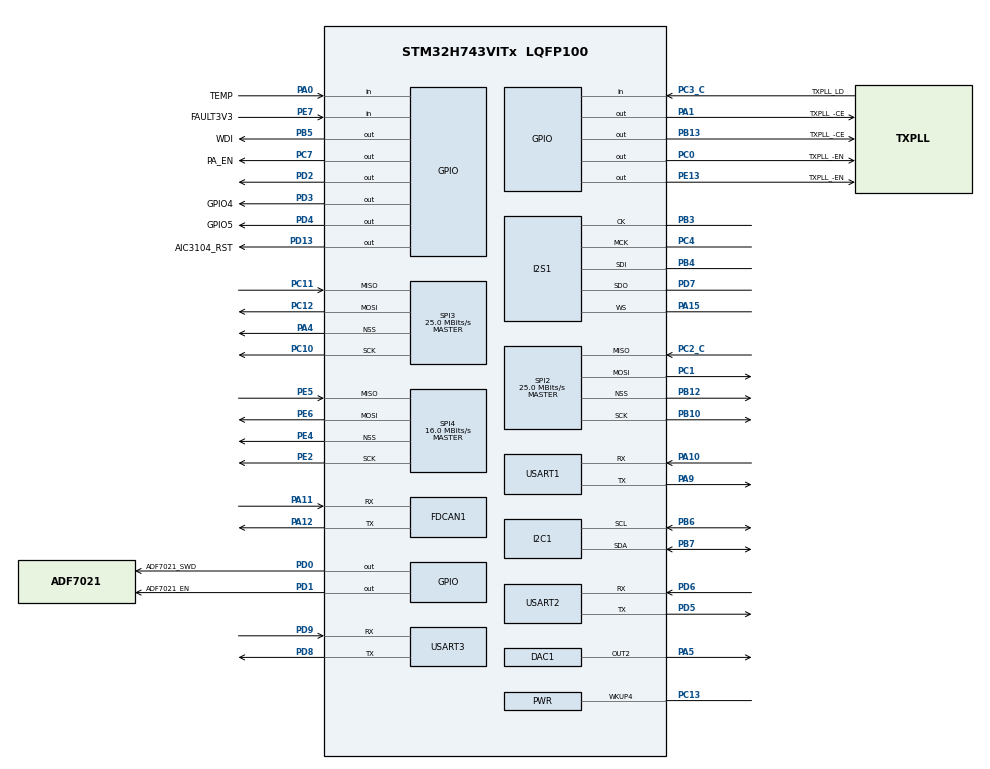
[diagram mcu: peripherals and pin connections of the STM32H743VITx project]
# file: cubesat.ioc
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CORTEX_M7.default_mode_Activation=1
DAC1.DAC_Channel-DAC_OUT2=DAC_CHANNEL_2
FDCAN1.CalculateBaudRateNominal=1041666
FDCAN1.CalculateTimeBitNominal=960
FDCAN1.CalculateTimeQuantumNominal=320.0
FDCAN1.TxBuffersNbr=32
FREERTOS.Tasks01=defaultTask,0,128,StartDefaultTask,Default,NULL,Dynamic,NULL,NULL
I2C1.Timing=0x00707CBB
I2S1.ErrorAudioFreq=1.72 %
I2S1.Instance=SPI$Index
I2S1.RealAudioFreq=8.138 KHz
Mcu.Family=STM32H7
Mcu.Name=STM32H743VITx
Mcu.Package=LQFP100
NVIC.PriorityGroup=NVIC_PRIORITYGROUP_4
NVIC.TIM1_UP_IRQn=true\:15\:0\:false\:false\:true\:false\:false\:true\:true
NVIC.TimeBase=TIM1_UP_IRQn
NVIC.TimeBaseIP=TIM1
PA0.GPIO_Label=TEMP
PA0.Signal=GPIO_Input
PA1.GPIO_Label=TXPLL_-CE
PA1.Signal=GPIO_Output
PA10.Mode=Asynchronous
PA10.Signal=USART1_RX
PA11.Mode=FDCAN_Activate
PA11.Signal=FDCAN1_RX
PA12.Mode=FDCAN_Activate
PA12.Signal=FDCAN1_TX
PA13\ (JTMS/SWDIO).Mode=Serial_Wire
PA13\ (JTMS/SWDIO).Signal=DEBUG_JTMS-SWDIO
PA14\ (JTCK/SWCLK).Mode=Serial_Wire
PA14\ (JTCK/SWCLK).Signal=DEBUG_JTCK-SWCLK
PA15\ (JTDI).Mode=Full_Duplex_Master
PA15\ (JTDI).Signal=I2S1_WS
PA4.Mode=NSS_Signal_Hard_Output
PA4.Signal=SPI3_NSS
PA5.Signal=COMP_DAC12_group
PA9.Mode=Asynchronous
PA9.Signal=USART1_TX
PB10.Mode=Full_Duplex_Master
PB10.Signal=SPI2_SCK
PB12.Mode=NSS_Signal_Hard_Output
PB12.Signal=SPI2_NSS
PB13.GPIO_Label=TXPLL_-CE
PB13.Signal=GPIO_Output
PB3\ (JTDO/TRACESWO).Mode=Full_Duplex_Master
PB3\ (JTDO/TRACESWO).Signal=I2S1_CK
PB4\ (NJTRST).Mode=Full_Duplex_Master
PB4\ (NJTRST).Signal=I2S1_SDI
PB5.GPIO_Label=WDI
PB5.Signal=GPIO_Output
PB6.Mode=I2C
PB6.Signal=I2C1_SCL
PB7.Mode=I2C
PB7.Signal=I2C1_SDA
PC0.GPIO_Label=TXPLL_-EN
PC0.Signal=GPIO_Output
PC1.Mode=Full_Duplex_Master
PC1.Signal=SPI2_MOSI
PC10.Mode=Full_Duplex_Master
PC10.Signal=SPI3_SCK
PC11.Mode=Full_Duplex_Master
PC11.Signal=SPI3_MISO
PC12.Mode=Full_Duplex_Master
PC12.Signal=SPI3_MOSI
PC13.Mode=WakeUp4
PC13.Signal=PWR_WKUP4
PC14-OSC32_IN\ (OSC32_IN).Mode=LSE-External-Clock-Source
PC14-OSC32_IN\ (OSC32_IN).Signal=RCC_OSC32_IN
PC2_C.Mode=Full_Duplex_Master
PC2_C.Signal=SPI2_MISO
PC3_C.GPIO_Label=TXPLL_LD
PC3_C.Signal=GPIO_Input
PC4.Mode=Master_Clock_Activated
PC4.Signal=I2S1_MCK
PC7.GPIO_Label=PA_EN
PC7.Signal=GPIO_Output
PD0.GPIO_Label=ADF7021_SWD
PD0.Signal=GPIO_Output
PD1.GPIO_Label=ADF7021_EN
PD1.Signal=GPIO_Output
PD13.GPIO_Label=AIC3104_RST
PD13.Signal=GPIO_Output
PD2.Signal=GPIO_Output
PD3.GPIO_Label=GPIO4
PD3.Signal=GPIO_Output
PD4.GPIO_Label=GPIO5
PD4.Signal=GPIO_Output
PD5.Mode=Asynchronous
PD5.Signal=USART2_TX
PD6.Mode=Asynchronous
PD6.Signal=USART2_RX
PD7.Mode=Full_Duplex_Master
PD7.Signal=I2S1_SDO
PD8.Mode=Asynchronous
PD8.Signal=USART3_TX
PD9.Mode=Asynchronous
PD9.Signal=USART3_RX
PE13.GPIO_Label=TXPLL_-EN
PE13.Signal=GPIO_Output
PE2.Mode=Full_Duplex_Master
PE2.Signal=SPI4_SCK
PE4.Mode=NSS_Signal_Hard_Output
PE4.Signal=SPI4_NSS
PE5.Mode=Full_Duplex_Master
PE5.Signal=SPI4_MISO
PE6.Mode=Full_Duplex_Master
PE6.Signal=SPI4_MOSI
PE7.GPIO_Label=FAULT3V3
PE7.Signal=GPIO_Input
PH0-OSC_IN\ (PH0).Mode=HSE-External-Clock-Source
PH0-OSC_IN\ (PH0).Signal=RCC_OSC_IN
ProjectManager.HeapSize=0x200
ProjectManager.StackSize=0x400
ProjectManager.TargetToolchain=CMake
RCC.ADCFreq_Value=129000000
RCC.APB1Freq_Value=32000000
RCC.APB2Freq_Value=32000000
RCC.APB3Freq_Value=64000000
RCC.APB4Freq_Value=32000000
RCC.CortexFreq_Value=64000000
RCC.D2PPRE1=RCC_APB1_DIV2
RCC.D2PPRE2=RCC_APB2_DIV2
RCC.D3PPRE=RCC_APB4_DIV2
RCC.DIVM1=4
RCC.DIVN1=9
RCC.DIVQ1=3
RCC.HCLKFreq_Value=64000000
RCC.PLL2FRACN=0
RCC.PLL3FRACN=0
RCC.PLLFRACN=3072
RCC.SYSCLKFreq_VALUE=64000000
RCC.USBFreq_Value=50000000
SH.COMP_DAC12_group.0=DAC1_OUT2,DAC_OUT2
SPI2.CalculateBaudRate=25.0 MBits/s
SPI2.Direction=SPI_DIRECTION_2LINES
SPI2.Mode=SPI_MODE_MASTER
SPI2.VirtualNSS=VM_NSSHARD
SPI2.VirtualType=VM_MASTER
SPI3.CalculateBaudRate=25.0 MBits/s
SPI3.Direction=SPI_DIRECTION_2LINES
SPI3.Mode=SPI_MODE_MASTER
SPI3.VirtualNSS=VM_NSSHARD
SPI3.VirtualType=VM_MASTER
SPI4.CalculateBaudRate=16.0 MBits/s
SPI4.Direction=SPI_DIRECTION_2LINES
SPI4.Mode=SPI_MODE_MASTER
SPI4.VirtualNSS=VM_NSSHARD
SPI4.VirtualType=VM_MASTER
STMicroelectronics.X-CUBE-ALGOBUILD.1.4.0.LibraryCcDSPOoLibraryJjDSPOoLibrary=true
USART1.VirtualMode-Asynchronous=VM_ASYNC
USART2.VirtualMode-Asynchronous=VM_ASYNC
USART3.VirtualMode-Asynchronous=VM_ASYNC
VP_FREERTOS_VS_CMSIS_V1.Mode=CMSIS_V1
VP_IWDG1_VS_IWDG.Mode=IWDG_Activate
VP_MEMORYMAP_VS_MEMORYMAP.Mode=CurAppReg
VP_STMicroelectronics.X-CUBE-ALGOBUILD_VS_DSPOoLibraryJjLibrary_1.4.0_1.4.0.Mode=DSPOoLibraryJjLibrary
VP_SYS_VS_tim1.Mode=TIM1
board=custom

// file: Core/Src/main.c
/* USER CODE BEGIN Header */
/**
  ******************************************************************************
  * @file           : main.c
  * @brief          : Main program body
  ******************************************************************************
  * @attention
  *
  * Copyright (c) 2026 STMicroelectronics.
  * All rights reserved.
  *
  * This software is licensed under terms that can be found in the LICENSE file
  * in the root directory of this software component.
  * If no LICENSE file comes with this software, it is provided AS-IS.
  *
  ******************************************************************************
  */
/* USER CODE END Header */
#include "main.h"
#include "cmsis_os.h"
#include "stm32h7xx_hal_dac.h"

/* USER CODE BEGIN Includes */
#include "aic3104.h"
/* USER CODE END Includes */

DAC_HandleTypeDef hdac1;

FDCAN_HandleTypeDef hfdcan1;

I2C_HandleTypeDef hi2c1;

I2S_HandleTypeDef hi2s1;

IWDG_HandleTypeDef hiwdg1;

SPI_HandleTypeDef hspi2;
SPI_HandleTypeDef hspi3;
SPI_HandleTypeDef hspi4;

UART_HandleTypeDef huart1;
UART_HandleTypeDef huart2;
UART_HandleTypeDef huart3;

osThreadId defaultTaskHandle;

void SystemClock_Config(void);
static void MPU_Config(void);
static void MX_GPIO_Init(void);
static void MX_FDCAN1_Init(void);
static void MX_I2S1_Init(void);
static void MX_SPI4_Init(void);
static void MX_SPI2_Init(void);
static void MX_SPI3_Init(void);
static void MX_DAC1_Init(void);
static void MX_I2C1_Init(void);
static void MX_IWDG1_Init(void);
static void MX_USART1_UART_Init(void);
static void MX_USART2_UART_Init(void);
static void MX_USART3_UART_Init(void);
void StartDefaultTask(void const * argument);

int main(void)
{

  /* MPU Configuration--------------------------------------------------------*/
  MPU_Config();

  /* MCU Configuration--------------------------------------------------------*/

  /* Reset of all peripherals, Initializes the Flash interface and the Systick. */
  HAL_Init();

  /* Configure the system clock */
  SystemClock_Config();

  /* Initialize all configured peripherals */
  MX_GPIO_Init();
  MX_FDCAN1_Init();
  MX_I2S1_Init();
  MX_SPI4_Init();
  MX_SPI2_Init();
  MX_SPI3_Init();
  MX_DAC1_Init();
  MX_I2C1_Init();
  MX_IWDG1_Init();
  MX_USART1_UART_Init();
  MX_USART2_UART_Init();
  MX_USART3_UART_Init();
  /* USER CODE BEGIN 2 */

  /* Initialize AIC3104 codec */
  AIC3104_Config_t aic3104_cfg = {
      .hi2c = &hi2c1,
      .hi2s = &hi2s1,
      .reset_port = GPIOD,
      .reset_pin = AIC3104_RST_Pin,
      .mclk_freq = 12288000,     /* 12.288 MHz MCLK */
      .sample_rate = AIC3104_FS_48K,
      .i2s_mode = AIC3104_MODE_MASTER
  };

  if (AIC3104_Init(&aic3104_cfg) != HAL_OK) {
      Error_Handler();
  }

  /* USER CODE END 2 */

  /* Create the thread(s) */
  /* definition and creation of defaultTask */
  osThreadDef(defaultTask, StartDefaultTask, osPriorityNormal, 0, 128);
  defaultTaskHandle = osThreadCreate(osThread(defaultTask), NULL);

  /* Start scheduler */
  osKernelStart();

  /* We should never get here as control is now taken by the scheduler */

  /* Infinite loop */
  while (1)
  {

  }
}

void SystemClock_Config(void)
{
  RCC_OscInitTypeDef RCC_OscInitStruct = {0};
  RCC_ClkInitTypeDef RCC_ClkInitStruct = {0};

  /** Supply configuration update enable
  */
  HAL_PWREx_ConfigSupply(PWR_LDO_SUPPLY);

  /** Configure the main internal regulator output voltage
  */
  __HAL_PWR_VOLTAGESCALING_CONFIG(PWR_REGULATOR_VOLTAGE_SCALE3);

  while(!__HAL_PWR_GET_FLAG(PWR_FLAG_VOSRDY)) {}

  /** Initializes the RCC Oscillators according to the specified parameters
  * in the RCC_OscInitTypeDef structure.
  */
  RCC_OscInitStruct.OscillatorType = RCC_OSCILLATORTYPE_HSI|RCC_OSCILLATORTYPE_LSI;
  RCC_OscInitStruct.HSIState = RCC_HSI_DIV1;
  RCC_OscInitStruct.HSICalibrationValue = RCC_HSICALIBRATION_DEFAULT;
  RCC_OscInitStruct.LSIState = RCC_LSI_ON;
  RCC_OscInitStruct.PLL.PLLState = RCC_PLL_ON;
  RCC_OscInitStruct.PLL.PLLSource = RCC_PLLSOURCE_HSI;
  RCC_OscInitStruct.PLL.PLLM = 4;
  RCC_OscInitStruct.PLL.PLLN = 9;
  RCC_OscInitStruct.PLL.PLLP = 2;
  RCC_OscInitStruct.PLL.PLLQ = 3;
  RCC_OscInitStruct.PLL.PLLR = 2;
  RCC_OscInitStruct.PLL.PLLRGE = RCC_PLL1VCIRANGE_3;
  RCC_OscInitStruct.PLL.PLLVCOSEL = RCC_PLL1VCOMEDIUM;
  RCC_OscInitStruct.PLL.PLLFRACN = 3072;
  if (HAL_RCC_OscConfig(&RCC_OscInitStruct) != HAL_OK)
  {
    Error_Handler();
  }

  /** Initializes the CPU, AHB and APB buses clocks
  */
  RCC_ClkInitStruct.ClockType = RCC_CLOCKTYPE_HCLK|RCC_CLOCKTYPE_SYSCLK
                              |RCC_CLOCKTYPE_PCLK1|RCC_CLOCKTYPE_PCLK2
                              |RCC_CLOCKTYPE_D3PCLK1|RCC_CLOCKTYPE_D1PCLK1;
  RCC_ClkInitStruct.SYSCLKSource = RCC_SYSCLKSOURCE_HSI;
  RCC_ClkInitStruct.SYSCLKDivider = RCC_SYSCLK_DIV1;
  RCC_ClkInitStruct.AHBCLKDivider = RCC_HCLK_DIV1;
  RCC_ClkInitStruct.APB3CLKDivider = RCC_APB3_DIV1;
  RCC_ClkInitStruct.APB1CLKDivider = RCC_APB1_DIV2;
  RCC_ClkInitStruct.APB2CLKDivider = RCC_APB2_DIV2;
  RCC_ClkInitStruct.APB4CLKDivider = RCC_APB4_DIV2;

  if (HAL_RCC_ClockConfig(&RCC_ClkInitStruct, FLASH_LATENCY_1) != HAL_OK)
  {
    Error_Handler();
  }
}

static void MX_DAC1_Init(void)
{

  DAC_ChannelConfTypeDef sConfig = {0};

  /** DAC Initialization
  */
  hdac1.Instance = DAC1;
  if (HAL_DAC_Init(&hdac1) != HAL_OK)
  {
    Error_Handler();
  }

  /** DAC channel OUT2 config
  */
  sConfig.DAC_SampleAndHold = DAC_SAMPLEANDHOLD_DISABLE;
  sConfig.DAC_Trigger = DAC_TRIGGER_NONE;
  sConfig.DAC_OutputBuffer = DAC_OUTPUTBUFFER_ENABLE;
  sConfig.DAC_ConnectOnChipPeripheral = DAC_CHIPCONNECT_DISABLE;
  sConfig.DAC_UserTrimming = DAC_TRIMMING_FACTORY;
  if (HAL_DAC_ConfigChannel(&hdac1, &sConfig, DAC_CHANNEL_2) != HAL_OK)
  {
    Error_Handler();
  }
  /* USER CODE BEGIN DAC1_Init 2 */
  HAL_DAC_SetValue(&hdac1, DAC_CHANNEL_2, DAC_ALIGN_12B_R, 2048);
  /* USER CODE END DAC1_Init 2 */

}

static void MX_FDCAN1_Init(void)
{

  hfdcan1.Instance = FDCAN1;
  hfdcan1.Init.FrameFormat = FDCAN_FRAME_CLASSIC;
  hfdcan1.Init.Mode = FDCAN_MODE_NORMAL;
  hfdcan1.Init.AutoRetransmission = DISABLE;
  hfdcan1.Init.TransmitPause = DISABLE;
  hfdcan1.Init.ProtocolException = DISABLE;
  hfdcan1.Init.NominalPrescaler = 16;
  hfdcan1.Init.NominalSyncJumpWidth = 1;
  hfdcan1.Init.NominalTimeSeg1 = 1;
  hfdcan1.Init.NominalTimeSeg2 = 1;
  hfdcan1.Init.DataPrescaler = 1;
  hfdcan1.Init.DataSyncJumpWidth = 1;
  hfdcan1.Init.DataTimeSeg1 = 1;
  hfdcan1.Init.DataTimeSeg2 = 1;
  hfdcan1.Init.MessageRAMOffset = 0;
  hfdcan1.Init.StdFiltersNbr = 0;
  hfdcan1.Init.ExtFiltersNbr = 0;
  hfdcan1.Init.RxFifo0ElmtsNbr = 0;
  hfdcan1.Init.RxFifo0ElmtSize = FDCAN_DATA_BYTES_8;
  hfdcan1.Init.RxFifo1ElmtsNbr = 0;
  hfdcan1.Init.RxFifo1ElmtSize = FDCAN_DATA_BYTES_8;
  hfdcan1.Init.RxBuffersNbr = 0;
  hfdcan1.Init.RxBufferSize = FDCAN_DATA_BYTES_8;
  hfdcan1.Init.TxEventsNbr = 0;
  hfdcan1.Init.TxBuffersNbr = 32;
  hfdcan1.Init.TxFifoQueueElmtsNbr = 0;
  hfdcan1.Init.TxFifoQueueMode = FDCAN_TX_FIFO_OPERATION;
  hfdcan1.Init.TxElmtSize = FDCAN_DATA_BYTES_8;
  if (HAL_FDCAN_Init(&hfdcan1) != HAL_OK)
  {
    Error_Handler();
  }

}

static void MX_I2C1_Init(void)
{

  hi2c1.Instance = I2C1;
  hi2c1.Init.Timing = 0x00707CBB;
  hi2c1.Init.OwnAddress1 = 0;
  hi2c1.Init.AddressingMode = I2C_ADDRESSINGMODE_7BIT;
  hi2c1.Init.DualAddressMode = I2C_DUALADDRESS_DISABLE;
  hi2c1.Init.OwnAddress2 = 0;
  hi2c1.Init.OwnAddress2Masks = I2C_OA2_NOMASK;
  hi2c1.Init.GeneralCallMode = I2C_GENERALCALL_DISABLE;
  hi2c1.Init.NoStretchMode = I2C_NOSTRETCH_DISABLE;
  if (HAL_I2C_Init(&hi2c1) != HAL_OK)
  {
    Error_Handler();
  }

  /** Configure Analogue filter
  */
  if (HAL_I2CEx_ConfigAnalogFilter(&hi2c1, I2C_ANALOGFILTER_ENABLE) != HAL_OK)
  {
    Error_Handler();
  }

  /** Configure Digital filter
  */
  if (HAL_I2CEx_ConfigDigitalFilter(&hi2c1, 0) != HAL_OK)
  {
    Error_Handler();
  }

}

static void MX_I2S1_Init(void)
{

  hi2s1.Instance = SPI1;
  hi2s1.Init.Mode = I2S_MODE_MASTER_FULLDUPLEX;
  hi2s1.Init.Standard = I2S_STANDARD_PHILIPS;
  hi2s1.Init.DataFormat = I2S_DATAFORMAT_16B;
  hi2s1.Init.MCLKOutput = I2S_MCLKOUTPUT_ENABLE;
  hi2s1.Init.AudioFreq = I2S_AUDIOFREQ_8K;
  hi2s1.Init.CPOL = I2S_CPOL_LOW;
  hi2s1.Init.FirstBit = I2S_FIRSTBIT_MSB;
  hi2s1.Init.WSInversion = I2S_WS_INVERSION_DISABLE;
  hi2s1.Init.Data24BitAlignment = I2S_DATA_24BIT_ALIGNMENT_RIGHT;
  hi2s1.Init.MasterKeepIOState = I2S_MASTER_KEEP_IO_STATE_DISABLE;
  if (HAL_I2S_Init(&hi2s1) != HAL_OK)
  {
    Error_Handler();
  }

}

static void MX_IWDG1_Init(void)
{

  hiwdg1.Instance = IWDG1;
  hiwdg1.Init.Prescaler = IWDG_PRESCALER_4;
  hiwdg1.Init.Window = 4095;
  hiwdg1.Init.Reload = 4095;
  if (HAL_IWDG_Init(&hiwdg1) != HAL_OK)
  {
    Error_Handler();
  }

}

static void MX_SPI2_Init(void)
{

  /* SPI2 parameter configuration*/
  hspi2.Instance = SPI2;
  hspi2.Init.Mode = SPI_MODE_MASTER;
  hspi2.Init.Direction = SPI_DIRECTION_2LINES;
  hspi2.Init.DataSize = SPI_DATASIZE_4BIT;
  hspi2.Init.CLKPolarity = SPI_POLARITY_LOW;
  hspi2.Init.CLKPhase = SPI_PHASE_1EDGE;
  hspi2.Init.NSS = SPI_NSS_HARD_OUTPUT;
  hspi2.Init.BaudRatePrescaler = SPI_BAUDRATEPRESCALER_2;
  hspi2.Init.FirstBit = SPI_FIRSTBIT_MSB;
  hspi2.Init.TIMode = SPI_TIMODE_DISABLE;
  hspi2.Init.CRCCalculation = SPI_CRCCALCULATION_DISABLE;
  hspi2.Init.CRCPolynomial = 0x0;
  hspi2.Init.NSSPMode = SPI_NSS_PULSE_ENABLE;
  hspi2.Init.NSSPolarity = SPI_NSS_POLARITY_LOW;
  hspi2.Init.FifoThreshold = SPI_FIFO_THRESHOLD_01DATA;
  hspi2.Init.TxCRCInitializationPattern = SPI_CRC_INITIALIZATION_ALL_ZERO_PATTERN;
  hspi2.Init.RxCRCInitializationPattern = SPI_CRC_INITIALIZATION_ALL_ZERO_PATTERN;
  hspi2.Init.MasterSSIdleness = SPI_MASTER_SS_IDLENESS_00CYCLE;
  hspi2.Init.MasterInterDataIdleness = SPI_MASTER_INTERDATA_IDLENESS_00CYCLE;
  hspi2.Init.MasterReceiverAutoSusp = SPI_MASTER_RX_AUTOSUSP_DISABLE;
  hspi2.Init.MasterKeepIOState = SPI_MASTER_KEEP_IO_STATE_DISABLE;
  hspi2.Init.IOSwap = SPI_IO_SWAP_DISABLE;
  if (HAL_SPI_Init(&hspi2) != HAL_OK)
  {
    Error_Handler();
  }

}

static void MX_SPI3_Init(void)
{

  /* SPI3 parameter configuration*/
  hspi3.Instance = SPI3;
  hspi3.Init.Mode = SPI_MODE_MASTER;
  hspi3.Init.Direction = SPI_DIRECTION_2LINES;
  hspi3.Init.DataSize = SPI_DATASIZE_4BIT;
  hspi3.Init.CLKPolarity = SPI_POLARITY_LOW;
  hspi3.Init.CLKPhase = SPI_PHASE_1EDGE;
  hspi3.Init.NSS = SPI_NSS_HARD_OUTPUT;
  hspi3.Init.BaudRatePrescaler = SPI_BAUDRATEPRESCALER_2;
  hspi3.Init.FirstBit = SPI_FIRSTBIT_MSB;
  hspi3.Init.TIMode = SPI_TIMODE_DISABLE;
  hspi3.Init.CRCCalculation = SPI_CRCCALCULATION_DISABLE;
  hspi3.Init.CRCPolynomial = 0x0;
  hspi3.Init.NSSPMode = SPI_NSS_PULSE_ENABLE;
  hspi3.Init.NSSPolarity = SPI_NSS_POLARITY_LOW;
  hspi3.Init.FifoThreshold = SPI_FIFO_THRESHOLD_01DATA;
  hspi3.Init.TxCRCInitializationPattern = SPI_CRC_INITIALIZATION_ALL_ZERO_PATTERN;
  hspi3.Init.RxCRCInitializationPattern = SPI_CRC_INITIALIZATION_ALL_ZERO_PATTERN;
  hspi3.Init.MasterSSIdleness = SPI_MASTER_SS_IDLENESS_00CYCLE;
  hspi3.Init.MasterInterDataIdleness = SPI_MASTER_INTERDATA_IDLENESS_00CYCLE;
  hspi3.Init.MasterReceiverAutoSusp = SPI_MASTER_RX_AUTOSUSP_DISABLE;
  hspi3.Init.MasterKeepIOState = SPI_MASTER_KEEP_IO_STATE_DISABLE;
  hspi3.Init.IOSwap = SPI_IO_SWAP_DISABLE;
  if (HAL_SPI_Init(&hspi3) != HAL_OK)
  {
    Error_Handler();
  }

}

static void MX_SPI4_Init(void)
{

  /* SPI4 parameter configuration*/
  hspi4.Instance = SPI4;
  hspi4.Init.Mode = SPI_MODE_MASTER;
  hspi4.Init.Direction = SPI_DIRECTION_2LINES;
  hspi4.Init.DataSize = SPI_DATASIZE_4BIT;
  hspi4.Init.CLKPolarity = SPI_POLARITY_LOW;
  hspi4.Init.CLKPhase = SPI_PHASE_1EDGE;
  hspi4.Init.NSS = SPI_NSS_HARD_OUTPUT;
  hspi4.Init.BaudRatePrescaler = SPI_BAUDRATEPRESCALER_2;
  hspi4.Init.FirstBit = SPI_FIRSTBIT_MSB;
  hspi4.Init.TIMode = SPI_TIMODE_DISABLE;
  hspi4.Init.CRCCalculation = SPI_CRCCALCULATION_DISABLE;
  hspi4.Init.CRCPolynomial = 0x0;
  hspi4.Init.NSSPMode = SPI_NSS_PULSE_ENABLE;
  hspi4.Init.NSSPolarity = SPI_NSS_POLARITY_LOW;
  hspi4.Init.FifoThreshold = SPI_FIFO_THRESHOLD_01DATA;
  hspi4.Init.TxCRCInitializationPattern = SPI_CRC_INITIALIZATION_ALL_ZERO_PATTERN;
  hspi4.Init.RxCRCInitializationPattern = SPI_CRC_INITIALIZATION_ALL_ZERO_PATTERN;
  hspi4.Init.MasterSSIdleness = SPI_MASTER_SS_IDLENESS_00CYCLE;
  hspi4.Init.MasterInterDataIdleness = SPI_MASTER_INTERDATA_IDLENESS_00CYCLE;
  hspi4.Init.MasterReceiverAutoSusp = SPI_MASTER_RX_AUTOSUSP_DISABLE;
  hspi4.Init.MasterKeepIOState = SPI_MASTER_KEEP_IO_STATE_DISABLE;
  hspi4.Init.IOSwap = SPI_IO_SWAP_DISABLE;
  if (HAL_SPI_Init(&hspi4) != HAL_OK)
  {
    Error_Handler();
  }

}

static void MX_USART1_UART_Init(void)
{

  huart1.Instance = USART1;
  huart1.Init.BaudRate = 115200;
  huart1.Init.WordLength = UART_WORDLENGTH_8B;
  huart1.Init.StopBits = UART_STOPBITS_1;
  huart1.Init.Parity = UART_PARITY_NONE;
  huart1.Init.Mode = UART_MODE_TX_RX;
  huart1.Init.HwFlowCtl = UART_HWCONTROL_NONE;
  huart1.Init.OverSampling = UART_OVERSAMPLING_16;
  huart1.Init.OneBitSampling = UART_ONE_BIT_SAMPLE_DISABLE;
  huart1.Init.ClockPrescaler = UART_PRESCALER_DIV1;
  huart1.AdvancedInit.AdvFeatureInit = UART_ADVFEATURE_NO_INIT;
  if (HAL_UART_Init(&huart1) != HAL_OK)
  {
    Error_Handler();
  }
  if (HAL_UARTEx_SetTxFifoThreshold(&huart1, UART_TXFIFO_THRESHOLD_1_8) != HAL_OK)
  {
    Error_Handler();
  }
  if (HAL_UARTEx_SetRxFifoThreshold(&huart1, UART_RXFIFO_THRESHOLD_1_8) != HAL_OK)
  {
    Error_Handler();
  }
  if (HAL_UARTEx_DisableFifoMode(&huart1) != HAL_OK)
  {
    Error_Handler();
  }

}

static void MX_USART2_UART_Init(void)
{

  huart2.Instance = USART2;
  huart2.Init.BaudRate = 115200;
  huart2.Init.WordLength = UART_WORDLENGTH_8B;
  huart2.Init.StopBits = UART_STOPBITS_1;
  huart2.Init.Parity = UART_PARITY_NONE;
  huart2.Init.Mode = UART_MODE_TX_RX;
  huart2.Init.HwFlowCtl = UART_HWCONTROL_NONE;
  huart2.Init.OverSampling = UART_OVERSAMPLING_16;
  huart2.Init.OneBitSampling = UART_ONE_BIT_SAMPLE_DISABLE;
  huart2.Init.ClockPrescaler = UART_PRESCALER_DIV1;
  huart2.AdvancedInit.AdvFeatureInit = UART_ADVFEATURE_NO_INIT;
  if (HAL_UART_Init(&huart2) != HAL_OK)
  {
    Error_Handler();
  }
  if (HAL_UARTEx_SetTxFifoThreshold(&huart2, UART_TXFIFO_THRESHOLD_1_8) != HAL_OK)
  {
    Error_Handler();
  }
  if (HAL_UARTEx_SetRxFifoThreshold(&huart2, UART_RXFIFO_THRESHOLD_1_8) != HAL_OK)
  {
    Error_Handler();
  }
  if (HAL_UARTEx_DisableFifoMode(&huart2) != HAL_OK)
  {
    Error_Handler();
  }

}

static void MX_USART3_UART_Init(void)
{

  huart3.Instance = USART3;
  huart3.Init.BaudRate = 115200;
  huart3.Init.WordLength = UART_WORDLENGTH_8B;
  huart3.Init.StopBits = UART_STOPBITS_1;
  huart3.Init.Parity = UART_PARITY_NONE;
  huart3.Init.Mode = UART_MODE_TX_RX;
  huart3.Init.HwFlowCtl = UART_HWCONTROL_NONE;
  huart3.Init.OverSampling = UART_OVERSAMPLING_16;
  huart3.Init.OneBitSampling = UART_ONE_BIT_SAMPLE_DISABLE;
  huart3.Init.ClockPrescaler = UART_PRESCALER_DIV1;
  huart3.AdvancedInit.AdvFeatureInit = UART_ADVFEATURE_NO_INIT;
  if (HAL_UART_Init(&huart3) != HAL_OK)
  {
    Error_Handler();
  }
  if (HAL_UARTEx_SetTxFifoThreshold(&huart3, UART_TXFIFO_THRESHOLD_1_8) != HAL_OK)
  {
    Error_Handler();
  }
  if (HAL_UARTEx_SetRxFifoThreshold(&huart3, UART_RXFIFO_THRESHOLD_1_8) != HAL_OK)
  {
    Error_Handler();
  }
  if (HAL_UARTEx_DisableFifoMode(&huart3) != HAL_OK)
  {
    Error_Handler();
  }

}

static void MX_GPIO_Init(void)
{
  GPIO_InitTypeDef GPIO_InitStruct = {0};

  /* GPIO Ports Clock Enable */
  __HAL_RCC_GPIOE_CLK_ENABLE();
  __HAL_RCC_GPIOC_CLK_ENABLE();
  __HAL_RCC_GPIOH_CLK_ENABLE();
  __HAL_RCC_GPIOA_CLK_ENABLE();
  __HAL_RCC_GPIOB_CLK_ENABLE();
  __HAL_RCC_GPIOD_CLK_ENABLE();

  /*Configure GPIO pin Output Level */
  HAL_GPIO_WritePin(GPIOC, TXPLL__EN_Pin|PA_EN_Pin, GPIO_PIN_RESET);

  /*Configure GPIO pin Output Level */
  HAL_GPIO_WritePin(TXPLL__CE_GPIO_Port, TXPLL__CE_Pin, GPIO_PIN_RESET);

  /*Configure GPIO pin Output Level */
  HAL_GPIO_WritePin(TXPLL__ENE13_GPIO_Port, TXPLL__ENE13_Pin, GPIO_PIN_RESET);

  /*Configure GPIO pin Output Level */
  HAL_GPIO_WritePin(GPIOB, TXPLL__CEB13_Pin|WDI_Pin, GPIO_PIN_RESET);

  /*Configure GPIO pin Output Level */
  HAL_GPIO_WritePin(GPIOD, AIC3104_RST_Pin|ADF7021_SWD_Pin|ADF7021_EN_Pin|GPIO_PIN_2
                          |GPIO4_Pin|GPIO5_Pin, GPIO_PIN_RESET);

  /*Configure GPIO pins : TXPLL__EN_Pin PA_EN_Pin */
  GPIO_InitStruct.Pin = TXPLL__EN_Pin|PA_EN_Pin;
  GPIO_InitStruct.Mode = GPIO_MODE_OUTPUT_PP;
  GPIO_InitStruct.Pull = GPIO_NOPULL;
  GPIO_InitStruct.Speed = GPIO_SPEED_FREQ_LOW;
  HAL_GPIO_Init(GPIOC, &GPIO_InitStruct);

  /*Configure GPIO pin : TXPLL_LD_Pin */
  GPIO_InitStruct.Pin = TXPLL_LD_Pin;
  GPIO_InitStruct.Mode = GPIO_MODE_INPUT;
  GPIO_InitStruct.Pull = GPIO_NOPULL;
  HAL_GPIO_Init(TXPLL_LD_GPIO_Port, &GPIO_InitStruct);

  /*Configure GPIO pin : TEMP_Pin */
  GPIO_InitStruct.Pin = TEMP_Pin;
  GPIO_InitStruct.Mode = GPIO_MODE_INPUT;
  GPIO_InitStruct.Pull = GPIO_NOPULL;
  HAL_GPIO_Init(TEMP_GPIO_Port, &GPIO_InitStruct);

  /*Configure GPIO pin : TXPLL__CE_Pin */
  GPIO_InitStruct.Pin = TXPLL__CE_Pin;
  GPIO_InitStruct.Mode = GPIO_MODE_OUTPUT_PP;
  GPIO_InitStruct.Pull = GPIO_NOPULL;
  GPIO_InitStruct.Speed = GPIO_SPEED_FREQ_LOW;
  HAL_GPIO_Init(TXPLL__CE_GPIO_Port, &GPIO_InitStruct);

  /*Configure GPIO pin : FAULT3V3_Pin */
  GPIO_InitStruct.Pin = FAULT3V3_Pin;
  GPIO_InitStruct.Mode = GPIO_MODE_INPUT;
  GPIO_InitStruct.Pull = GPIO_NOPULL;
  HAL_GPIO_Init(FAULT3V3_GPIO_Port, &GPIO_InitStruct);

  /*Configure GPIO pin : TXPLL__ENE13_Pin */
  GPIO_InitStruct.Pin = TXPLL__ENE13_Pin;
  GPIO_InitStruct.Mode = GPIO_MODE_OUTPUT_PP;
  GPIO_InitStruct.Pull = GPIO_NOPULL;
  GPIO_InitStruct.Speed = GPIO_SPEED_FREQ_LOW;
  HAL_GPIO_Init(TXPLL__ENE13_GPIO_Port, &GPIO_InitStruct);

  /*Configure GPIO pins : TXPLL__CEB13_Pin WDI_Pin */
  GPIO_InitStruct.Pin = TXPLL__CEB13_Pin|WDI_Pin;
  GPIO_InitStruct.Mode = GPIO_MODE_OUTPUT_PP;
  GPIO_InitStruct.Pull = GPIO_NOPULL;
  GPIO_InitStruct.Speed = GPIO_SPEED_FREQ_LOW;
  HAL_GPIO_Init(GPIOB, &GPIO_InitStruct);

  /*Configure GPIO pins : AIC3104_RST_Pin ADF7021_SWD_Pin ADF7021_EN_Pin PD2
                           GPIO4_Pin GPIO5_Pin */
  GPIO_InitStruct.Pin = AIC3104_RST_Pin|ADF7021_SWD_Pin|ADF7021_EN_Pin|GPIO_PIN_2
                          |GPIO4_Pin|GPIO5_Pin;
  GPIO_InitStruct.Mode = GPIO_MODE_OUTPUT_PP;
  GPIO_InitStruct.Pull = GPIO_NOPULL;
  GPIO_InitStruct.Speed = GPIO_SPEED_FREQ_LOW;
  HAL_GPIO_Init(GPIOD, &GPIO_InitStruct);

  /*AnalogSwitch Config */
  HAL_SYSCFG_AnalogSwitchConfig(SYSCFG_SWITCH_PA1, SYSCFG_SWITCH_PA1_CLOSE);

}

void StartDefaultTask(void const * argument)
{
  for(;;)
  {
    osDelay(1);
  }
}

 /* MPU Configuration */

void MPU_Config(void)
{
  MPU_Region_InitTypeDef MPU_InitStruct = {0};

  /* Disables the MPU */
  HAL_MPU_Disable();

  /** Initializes and configures the Region and the memory to be protected
  */
  MPU_InitStruct.Enable = MPU_REGION_ENABLE;
  MPU_InitStruct.Number = MPU_REGION_NUMBER0;
  MPU_InitStruct.BaseAddress = 0x0;
  MPU_InitStruct.Size = MPU_REGION_SIZE_4GB;
  MPU_InitStruct.SubRegionDisable = 0x87;
  MPU_InitStruct.TypeExtField = MPU_TEX_LEVEL0;
  MPU_InitStruct.AccessPermission = MPU_REGION_NO_ACCESS;
  MPU_InitStruct.DisableExec = MPU_INSTRUCTION_ACCESS_DISABLE;
  MPU_InitStruct.IsShareable = MPU_ACCESS_SHAREABLE;
  MPU_InitStruct.IsCacheable = MPU_ACCESS_NOT_CACHEABLE;
  MPU_InitStruct.IsBufferable = MPU_ACCESS_NOT_BUFFERABLE;

  HAL_MPU_ConfigRegion(&MPU_InitStruct);
  /* Enables the MPU */
  HAL_MPU_Enable(MPU_PRIVILEGED_DEFAULT);

}

void HAL_TIM_PeriodElapsedCallback(TIM_HandleTypeDef *htim)
{
  if (htim->Instance == TIM1)
  {
    HAL_IncTick();
  }
}

void Error_Handler(void)
{
  __disable_irq();
  while (1)
  {
  }
}
